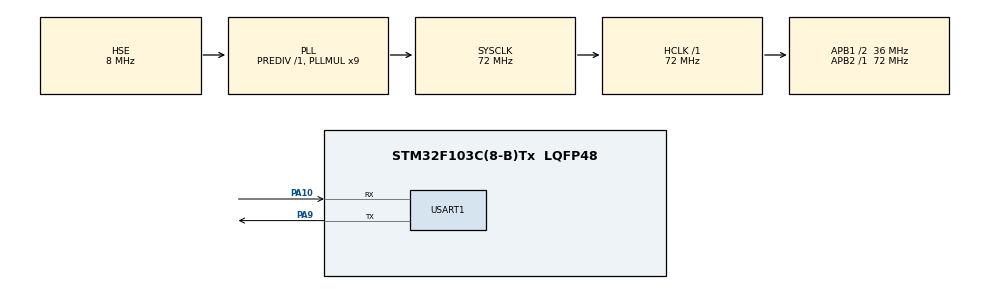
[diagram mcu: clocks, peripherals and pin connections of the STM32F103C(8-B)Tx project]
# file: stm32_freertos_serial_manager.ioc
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Dma.Request0=USART1_RX
Dma.Request1=USART1_TX
Dma.USART1_RX.0.Direction=DMA_PERIPH_TO_MEMORY
Dma.USART1_RX.0.Instance=DMA1_Channel5
Dma.USART1_RX.0.MemDataAlignment=DMA_MDATAALIGN_BYTE
Dma.USART1_RX.0.MemInc=DMA_MINC_ENABLE
Dma.USART1_RX.0.Mode=DMA_NORMAL
Dma.USART1_RX.0.PeriphDataAlignment=DMA_PDATAALIGN_BYTE
Dma.USART1_RX.0.PeriphInc=DMA_PINC_DISABLE
Dma.USART1_RX.0.Priority=DMA_PRIORITY_HIGH
Dma.USART1_TX.1.Direction=DMA_MEMORY_TO_PERIPH
Dma.USART1_TX.1.Instance=DMA1_Channel4
Dma.USART1_TX.1.MemDataAlignment=DMA_MDATAALIGN_BYTE
Dma.USART1_TX.1.MemInc=DMA_MINC_ENABLE
Dma.USART1_TX.1.Mode=DMA_NORMAL
Dma.USART1_TX.1.PeriphDataAlignment=DMA_PDATAALIGN_BYTE
Dma.USART1_TX.1.PeriphInc=DMA_PINC_DISABLE
Dma.USART1_TX.1.Priority=DMA_PRIORITY_MEDIUM
FREERTOS.Tasks01=DeviceTask,24,192,StartDeviceTask,Default,NULL,Dynamic,NULL,NULL;CommTask,32,256,StartCommTask,Default,NULL,Dynamic,NULL,NULL
FREERTOS.configCHECK_FOR_STACK_OVERFLOW=2
FREERTOS.configTOTAL_HEAP_SIZE=8192
FREERTOS.configUSE_MALLOC_FAILED_HOOK=1
Mcu.Family=STM32F1
Mcu.Name=STM32F103C(8-B)Tx
Mcu.Package=LQFP48
NVIC.DMA1_Channel4_IRQn=true\:5\:0\:false\:false\:true\:true\:false\:true\:true
NVIC.DMA1_Channel5_IRQn=true\:5\:0\:false\:false\:true\:true\:false\:true\:true
NVIC.PriorityGroup=NVIC_PRIORITYGROUP_4
NVIC.TIM2_IRQn=true\:15\:0\:false\:false\:true\:false\:false\:true\:true
NVIC.TimeBase=TIM2_IRQn
NVIC.TimeBaseIP=TIM2
NVIC.USART1_IRQn=true\:5\:0\:false\:false\:true\:true\:false\:true\:true
PA10.Mode=Asynchronous
PA10.Signal=USART1_RX
PA13.Mode=Serial_Wire
PA13.Signal=SYS_JTMS-SWDIO
PA14.Mode=Serial_Wire
PA14.Signal=SYS_JTCK-SWCLK
PA9.Mode=Asynchronous
PA9.Signal=USART1_TX
PD0-OSC_IN.Mode=HSE-External-Oscillator
PD0-OSC_IN.Signal=RCC_OSC_IN
PD1-OSC_OUT.Mode=HSE-External-Oscillator
PD1-OSC_OUT.Signal=RCC_OSC_OUT
ProjectManager.HeapSize=0x200
ProjectManager.StackSize=0x400
ProjectManager.TargetToolchain=MDK-ARM V5.32
RCC.AHBFreq_Value=72000000
RCC.APB1CLKDivider=RCC_HCLK_DIV2
RCC.APB1Freq_Value=36000000
RCC.APB1TimFreq_Value=72000000
RCC.APB2Freq_Value=72000000
RCC.APB2TimFreq_Value=72000000
RCC.HCLKFreq_Value=72000000
RCC.PLLMUL=RCC_PLL_MUL9
RCC.PLLSourceVirtual=RCC_PLLSOURCE_HSE
RCC.SYSCLKFreq_VALUE=72000000
RCC.SYSCLKSource=RCC_SYSCLKSOURCE_PLLCLK
RCC.USBFreq_Value=72000000
USART1.VirtualMode=VM_ASYNC
VP_FREERTOS_VS_CMSIS_V2.Mode=CMSIS_V2
VP_SYS_VS_tim2.Mode=TIM2
board=custom

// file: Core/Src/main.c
/* USER CODE BEGIN Header */
/**
  ******************************************************************************
  * @file           : main.c
  * @brief          : Main program body
  ******************************************************************************
  * @attention
  *
  * Copyright (c) 2026 STMicroelectronics.
  * All rights reserved.
  *
  * This software is licensed under terms that can be found in the LICENSE file
  * in the root directory of this software component.
  * If no LICENSE file comes with this software, it is provided AS-IS.
  *
  ******************************************************************************
  */
/* USER CODE END Header */
#include "main.h"
#include "cmsis_os.h"
#include "dma.h"
#include "usart.h"
#include "gpio.h"

void SystemClock_Config(void);
void MX_FREERTOS_Init(void);

int main(void)
{

  /* MCU Configuration--------------------------------------------------------*/

  /* Reset of all peripherals, Initializes the Flash interface and the Systick. */
  HAL_Init();

  /* Configure the system clock */
  SystemClock_Config();

  /* Initialize all configured peripherals */
  MX_GPIO_Init();
  MX_DMA_Init();
  MX_USART1_UART_Init();

  /* Init scheduler */
  osKernelInitialize();  /* Call init function for freertos objects (in cmsis_os2.c) */
  MX_FREERTOS_Init();

  /* Start scheduler */
  osKernelStart();

  /* We should never get here as control is now taken by the scheduler */

  /* Infinite loop */
  while (1)
  {

  }
}

void SystemClock_Config(void)
{
  RCC_OscInitTypeDef RCC_OscInitStruct = {0};
  RCC_ClkInitTypeDef RCC_ClkInitStruct = {0};

  /** Initializes the RCC Oscillators according to the specified parameters
  * in the RCC_OscInitTypeDef structure.
  */
  RCC_OscInitStruct.OscillatorType = RCC_OSCILLATORTYPE_HSE;
  RCC_OscInitStruct.HSEState = RCC_HSE_ON;
  RCC_OscInitStruct.HSEPredivValue = RCC_HSE_PREDIV_DIV1;
  RCC_OscInitStruct.HSIState = RCC_HSI_ON;
  RCC_OscInitStruct.PLL.PLLState = RCC_PLL_ON;
  RCC_OscInitStruct.PLL.PLLSource = RCC_PLLSOURCE_HSE;
  RCC_OscInitStruct.PLL.PLLMUL = RCC_PLL_MUL9;
  if (HAL_RCC_OscConfig(&RCC_OscInitStruct) != HAL_OK)
  {
    Error_Handler();
  }

  /** Initializes the CPU, AHB and APB buses clocks
  */
  RCC_ClkInitStruct.ClockType = RCC_CLOCKTYPE_HCLK|RCC_CLOCKTYPE_SYSCLK
                              |RCC_CLOCKTYPE_PCLK1|RCC_CLOCKTYPE_PCLK2;
  RCC_ClkInitStruct.SYSCLKSource = RCC_SYSCLKSOURCE_PLLCLK;
  RCC_ClkInitStruct.AHBCLKDivider = RCC_SYSCLK_DIV1;
  RCC_ClkInitStruct.APB1CLKDivider = RCC_HCLK_DIV2;
  RCC_ClkInitStruct.APB2CLKDivider = RCC_HCLK_DIV1;

  if (HAL_RCC_ClockConfig(&RCC_ClkInitStruct, FLASH_LATENCY_2) != HAL_OK)
  {
    Error_Handler();
  }
}

void HAL_TIM_PeriodElapsedCallback(TIM_HandleTypeDef *htim)
{
  if (htim->Instance == TIM2)
  {
    HAL_IncTick();
  }
}

void Error_Handler(void)
{
  __disable_irq();
  while (1)
  {
  }
}

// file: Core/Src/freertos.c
/* USER CODE BEGIN Header */
/**
  ******************************************************************************
  * File Name          : freertos.c
  * Description        : Code for freertos applications
  ******************************************************************************
  * @attention
  *
  * Copyright (c) 2026 STMicroelectronics.
  * All rights reserved.
  *
  * This software is licensed under terms that can be found in the LICENSE file
  * in the root directory of this software component.
  * If no LICENSE file comes with this software, it is provided AS-IS.
  *
  ******************************************************************************
  */
/* USER CODE END Header */

#include "FreeRTOS.h"
#include "task.h"
#include "main.h"
#include "cmsis_os.h"

/* USER CODE BEGIN Includes */
#include "usart.h"
#include "ring_buffer.h"
#include "protocol.h"
#include "crc16.h"
#include "device_manager.h"
/* USER CODE END Includes */

/* USER CODE BEGIN PD */
/* Receive-to-IDLE 每批最多接收 128 bytes，与 Normal DMA 的单次接收长度一致。 */
#define UART_RX_DMA_BUFFER_SIZE 128U
/* USER CODE END PD */

/* USER CODE BEGIN Variables */
/* 仅用于调试器观察任务活性：DeviceTask 按取队列超时计数，CommTask 按接收批次计数。 */
volatile uint32_t device_alive = 0;
volatile uint32_t comm_alive = 0;

/*
 * DMA 直接写入 uart_rx_dma_buffer；HAL 回调发布有效长度和 ready 标志，CommTask 消费。
 * volatile 仅让 ISR/任务的访问落到实际内存，不提供互斥、事件排队或多生产者同步。
 */
static uint8_t uart_rx_dma_buffer[UART_RX_DMA_BUFFER_SIZE];
static volatile uint16_t uart_rx_length = 0U;
static volatile uint8_t uart_rx_ready = 0U;
/* 运行期诊断计数器只供本地观察，当前协议没有读取这些统计值的命令。 */
volatile uint16_t ping_count = 0U;
volatile uint16_t frame_count = 0U;
volatile uint16_t crc_error_count = 0U;
volatile uint16_t queue_drop_count = 0U;
/* CommTask 生产完整且 CRC 正确的帧，DeviceTask 按值取走并负责业务处理。 */
osMessageQueueId_t ProtocolQueueHandle;
const osMessageQueueAttr_t ProtocolQueue_attributes = {
    .name = "ProtocolQueue"
};
/* USER CODE END Variables */
/* Definitions for DeviceTask */
osThreadId_t DeviceTaskHandle;
const osThreadAttr_t DeviceTask_attributes = {
  .name = "DeviceTask",
  .stack_size = 192 * 4,
  .priority = (osPriority_t) osPriorityNormal,
};
/* Definitions for CommTask */
osThreadId_t CommTaskHandle;
const osThreadAttr_t CommTask_attributes = {
  .name = "CommTask",
  .stack_size = 256 * 4,
  .priority = (osPriority_t) osPriorityAboveNormal,
};

/* USER CODE BEGIN FunctionPrototypes */
/*
 * Parser 只负责组帧，因此入队前在此校验 CRC。
 * 计算范围为 [LEN, CMD, DATA...]，接收值按 CRC_H、CRC_L 组合。
 */
static bool ProtocolFrame_CrcOk(const ProtocolFrame_t* frame)
{
  uint8_t crc_data[2U + PROTOCOL_MAX_DATA_LEN];
  uint8_t i;
  crc_data[0] = frame->len;
  crc_data[1] = frame->cmd;
  for (i = 0; i < frame->len; i++)
  {
    crc_data[2U + i] = frame->data[i];
  }
  uint16_t length = (uint16_t)(2U + frame->len);
  return (uint16_t)(((uint16_t)frame->crc_hi << 8U) | (uint16_t)frame->crc_lo) == CRC16_CCITT_FALSE_Calc(crc_data, length);
}

static void DeviceTask_SendErrorResponse(uint8_t failed_cmd,uint8_t error_code)
{
  /* 错误响应固定为 AA 02 FF failed_cmd error_code CRC_H CRC_L。 */
  uint8_t resp[PROTOCOL_MAX_DATA_LEN];
  const uint8_t sof = 0xAAU;
  resp[0] = sof;
  resp[1] = 2U;
  resp[2] = RESP_ERROR;
  resp[3] = failed_cmd;
  resp[4] = error_code;
  uint16_t crc = CRC16_CCITT_FALSE_Calc(&resp[1], 4U);
  resp[5] = (uint8_t)(crc >> 8U);
  resp[6] = (uint8_t)(crc & 0xFFU);
  /* 当前发送路径是阻塞式；超时或 HAL 错误统一进入 Error_Handler。 */
  if (HAL_UART_Transmit(&huart1, resp, 7U, 100U) != HAL_OK)
  {
    Error_Handler();
  }
}
/* USER CODE END FunctionPrototypes */

void StartDeviceTask(void *argument);
void StartCommTask(void *argument);

void MX_FREERTOS_Init(void); /* (MISRA C 2004 rule 8.1) */

/* Hook prototypes */
void vApplicationStackOverflowHook(xTaskHandle xTask, signed char *pcTaskName);
void vApplicationMallocFailedHook(void);

/* USER CODE BEGIN 4 */
void vApplicationStackOverflowHook(xTaskHandle xTask, signed char *pcTaskName)
{
   /* Run time stack overflow checking is performed if
   configCHECK_FOR_STACK_OVERFLOW is defined to 1 or 2. This hook function is
   called if a stack overflow is detected. */
}
/* USER CODE END 4 */

/* USER CODE BEGIN 5 */
void vApplicationMallocFailedHook(void)
{
   /* vApplicationMallocFailedHook() will only be called if
   configUSE_MALLOC_FAILED_HOOK is set to 1 in FreeRTOSConfig.h. It is a hook
   function that will get called if a call to pvPortMalloc() fails.
   pvPortMalloc() is called internally by the kernel whenever a task, queue,
   timer or semaphore is created. It is also called by various parts of the
   demo application. If heap_1.c or heap_2.c are used, then the size of the
   heap available to pvPortMalloc() is defined by configTOTAL_HEAP_SIZE in
   FreeRTOSConfig.h, and the xPortGetFreeHeapSize() API function can be used
   to query the size of free heap space that remains (although it does not
   provide information on how the remaining heap might be fragmented). */
}
/* USER CODE END 5 */

void MX_FREERTOS_Init(void) {

  /* USER CODE BEGIN RTOS_QUEUES */
  /* add queues, ... */
  /* 队列按值复制 ProtocolFrame_t，避免两个任务共享 Parser 的输出对象。 */
  ProtocolQueueHandle = osMessageQueueNew(8, sizeof(ProtocolFrame_t), &ProtocolQueue_attributes);
  /* USER CODE END RTOS_QUEUES */

  /* Create the thread(s) */
  /* creation of DeviceTask */
  DeviceTaskHandle = osThreadNew(StartDeviceTask, NULL, &DeviceTask_attributes);

  /* creation of CommTask */
  CommTaskHandle = osThreadNew(StartCommTask, NULL, &CommTask_attributes);

}

void StartDeviceTask(void *argument)
{
  /* USER CODE BEGIN StartDeviceTask */
  ProtocolFrame_t frame = { 0 };
  uint8_t resp[PROTOCOL_MAX_DATA_LEN];
  const uint8_t sof = 0xAAU;
  /* DeviceTask 是 DeviceManager 状态的唯一业务访问者，处理首帧前先复位为 IDLE。 */
  DeviceManager_Init();
  DeviceState_t current_state;

  /* Infinite loop */
  for(;;)
  {
    /* 串行处理请求；1 s 取队列超时仅用于更新任务活性计数。 */
    if (osMessageQueueGet(ProtocolQueueHandle, &frame, NULL, 1000U) == osOK)
    {
      switch (frame.cmd)
      {
      case CMD_PING:
      {
        /* 当前 PING 分支不检查请求 LEN，始终返回空 DATA 的 PING 响应。 */
        resp[0] = sof;
        resp[1] = 0U;
        resp[2] = CMD_PING_RESP;
        uint16_t crc = CRC16_CCITT_FALSE_Calc(&resp[1], 2U);
        resp[3] = (uint8_t)(crc >> 8U);
        resp[4] = (uint8_t)(crc & 0xFFU);
        if (HAL_UART_Transmit(&huart1, resp, 5U, 100U) != HAL_OK)
        {
          Error_Handler();
        }

        ping_count++;
      }
      break;
      case CMD_GET_STATUS:
      {
        if (frame.len != 0U)
        {
          DeviceTask_SendErrorResponse(CMD_GET_STATUS, ERR_INVALID_LENGTH);
          break;
        }
        resp[0] = sof;
        resp[1] = 1U;
        resp[2] = RESP_GET_STATUS;
        current_state = DeviceManager_GetState();
        resp[3] = current_state.mode;
        uint16_t crc = CRC16_CCITT_FALSE_Calc(&resp[1], 3U);
        resp[4] = (uint8_t)(crc >> 8U);
        resp[5] = (uint8_t)(crc & 0xFFU);
        if (HAL_UART_Transmit(&huart1, resp, 6U, 100U) != HAL_OK)
        {
          Error_Handler();
        }
      }
      break;
      case CMD_SET_MODE:
      {
        if (frame.len != 1U)
        {
          DeviceTask_SendErrorResponse(CMD_SET_MODE, ERR_INVALID_LENGTH);
          break;
        }
        /* DeviceManager 只接受已定义模式；失败时不会改变原状态。 */
        if (DeviceManager_SetMode(frame.data[0]))
        {
          resp[0] = sof;
          resp[1] = 1U;
          resp[2] = RESP_SET_MODE;
          resp[3] = frame.data[0];
          uint16_t crc = CRC16_CCITT_FALSE_Calc(&resp[1], 3U);
          resp[4] = (uint8_t)(crc >> 8U);
          resp[5] = (uint8_t)(crc & 0xFFU);
          if (HAL_UART_Transmit(&huart1, resp, 6U, 100U) != HAL_OK)
          {
            Error_Handler();
          }
        }
        else
        {
          DeviceTask_SendErrorResponse(CMD_SET_MODE, ERR_INVALID_PARAM);
        }
      }
      break;
      default:
        DeviceTask_SendErrorResponse(frame.cmd, ERR_UNKNOWN_CMD);
        break;
      }
    }
    else
    {
      device_alive++;
    }
  }
  /* USER CODE END StartDeviceTask */
}

void StartCommTask(void *argument)
{
  /* USER CODE BEGIN StartCommTask */
  uint16_t echo_length;
  HAL_StatusTypeDef rx_status;
  ProtocolParser_t parser;
  ProtocolFrame_t frame = {0};
  uint8_t byte;
  uint8_t write_count = 0U;

  /* Ring Buffer 和 Parser 均由 CommTask 独占，状态可以安全地跨 DMA 批次保留。 */
  RingBuffer_Init();
  ProtocolParser_Init(&parser);

  /* Normal DMA 在 IDLE 或传输完成后停止，因此每个批次都必须由任务重新启动。 */
  rx_status = HAL_UARTEx_ReceiveToIdle_DMA(
    &huart1,
    uart_rx_dma_buffer,
    UART_RX_DMA_BUFFER_SIZE
  );
  if (rx_status != HAL_OK)
  {
    Error_Handler();
  }
  /* 本实现按 IDLE/Transfer Complete 处理整批数据，不消费 Half Transfer 事件。 */
  __HAL_DMA_DISABLE_IT(huart1.hdmarx,DMA_IT_HT);
  /* Infinite loop */
  for(;;)
  {
    if (uart_rx_ready != 0U)
    {
      /* 先快照回调发布的长度，再把 DMA 缓冲区内容复制到任务私有的 Ring Buffer。 */
      echo_length = uart_rx_length;
      for (uint8_t i = 0U; i < echo_length; i++)
      {
        if (!RingBuffer_Writer(uart_rx_dma_buffer[i]))
        {
          /* 写满时停止复制，本批次尚未写入的字节不会进入 Parser。 */
          break;
        }
        write_count++;
      }

      uart_rx_ready = 0U;
      uart_rx_length = 0U;

      /* 复制完成后先重启接收，再解析 Ring Buffer 中与 DMA 存储区解耦的数据。 */
      rx_status = HAL_UARTEx_ReceiveToIdle_DMA(
        &huart1,
        uart_rx_dma_buffer,
        UART_RX_DMA_BUFFER_SIZE
      );
      if (rx_status != HAL_OK)
      {
        Error_Handler();
      }
      __HAL_DMA_DISABLE_IT(huart1.hdmarx, DMA_IT_HT);

      /* 只读取本批实际成功写入 Ring Buffer 的字节数。 */
      for (uint8_t i = 0U; i < write_count; i++)
      {
        if (RingBuffer_Read(&byte))
        {
          if (ProtocolParser_InputByte(&parser, byte, &frame))
          {
            /* 完整帧先校验 CRC，再以零等待方式入队；队列满时只记录丢帧。 */
            if (ProtocolFrame_CrcOk(&frame))
            {
              if (osMessageQueuePut(ProtocolQueueHandle, &frame, 0U, 0U) == osOK)
              {
                frame_count++;
              }
              else
              {
                queue_drop_count++;
              }
            }
            else
            {
              crc_error_count++;
            }
          }
        }
      }
      comm_alive++;
      write_count = 0U;
    }
    else
    osDelay(1);
  }
  /* USER CODE END StartCommTask */
}

/* USER CODE BEGIN Application */
/*
 * HAL UART 回调运行在中断上下文，只发布本批次长度和 ready 标志。
 * 数据复制、DMA 重启、Parser 和 RTOS Queue 操作全部留在 CommTask 中执行。
 */
void HAL_UARTEx_RxEventCallback(UART_HandleTypeDef* huart, uint16_t Size)
{
  if (huart->Instance == USART1)
  {
    uart_rx_length = Size;
    uart_rx_ready = 1U;
  }
}
/* USER CODE END Application */
